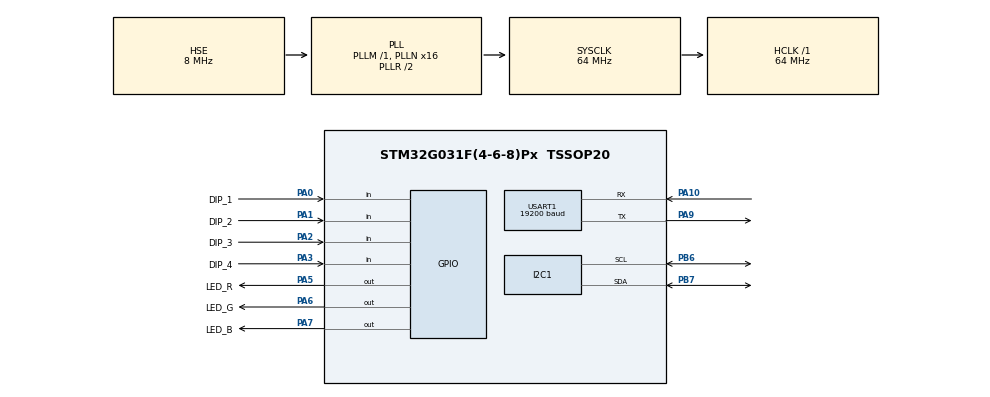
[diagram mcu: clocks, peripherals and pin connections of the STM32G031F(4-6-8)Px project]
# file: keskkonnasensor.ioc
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I2C1.Timing=0x10B17DB5
Mcu.Family=STM32G0
Mcu.Name=STM32G031F(4-6-8)Px
Mcu.Package=TSSOP20
PA0.GPIO_Label=DIP_1
PA0.GPIO_PuPd=GPIO_PULLUP
PA0.Signal=GPIO_Input
PA1.GPIO_Label=DIP_2
PA1.GPIO_PuPd=GPIO_PULLUP
PA1.Signal=GPIO_Input
PA10\ [PA12].Mode=Asynchronous
PA10\ [PA12].Signal=USART1_RX
PA13.Mode=Serial_Wire
PA13.Signal=SYS_SWDIO
PA14-BOOT0.Mode=Serial_Wire
PA14-BOOT0.Signal=SYS_SWCLK
PA14-BOOT0__PA15.StandardMode=true
PA2.GPIO_Label=DIP_3
PA2.GPIO_PuPd=GPIO_PULLUP
PA2.Signal=GPIO_Input
PA3.GPIO_Label=DIP_4
PA3.GPIO_PuPd=GPIO_PULLUP
PA3.Signal=GPIO_Input
PA5.GPIO_Label=LED_R
PA5.Signal=GPIO_Output
PA6.GPIO_Label=LED_G
PA6.Signal=GPIO_Output
PA7.GPIO_Label=LED_B
PA7.Signal=GPIO_Output
PA9\ [PA11].Mode=Asynchronous
PA9\ [PA11].Signal=USART1_TX
PB0__PB1__PB2__PA8.StandardMode=true
PB3__PB4__PB5__PB6.StandardMode=true
PB6.Mode=I2C
PB6.Signal=I2C1_SCL
PB7.Mode=I2C
PB7.Signal=I2C1_SDA
PB7__PB8.StandardMode=true
PC14-OSC32_IN\ (PC14).Mode=HSE-External-Clock-Source
PC14-OSC32_IN\ (PC14).Signal=RCC_OSC_IN
PC14-OSC32_IN\ (PC14)__PB9.StandardMode=true
ProjectManager.HeapSize=0x200
ProjectManager.StackSize=0x400
ProjectManager.TargetToolchain=CMake
RCC.ADCFreq_Value=64000000
RCC.AHBFreq_Value=64000000
RCC.CortexFreq_Value=64000000
RCC.EXTERNAL_CLOCK_VALUE=12288000
RCC.HCLKFreq_Value=64000000
RCC.HSE_VALUE=8000000
RCC.HSI_VALUE=16000000
RCC.LSE_VALUE=32768
RCC.PLLN=16
RCC.PLLSourceVirtual=RCC_PLLSOURCE_HSE
RCC.SYSCLKFreq_VALUE=64000000
RCC.SYSCLKSource=RCC_SYSCLKSOURCE_PLLCLK
RCC.VCOOutputFreq_Value=128000000
USART1.BaudRate=19200
USART1.Parity=PARITY_EVEN
USART1.VirtualMode-Asynchronous=VM_ASYNC
USART1.WordLength=WORDLENGTH_9B
VP_SYS_VS_PINREMAP.Mode=PINREMAP
VP_SYS_VS_PINREMAP_10_12.Mode=PINREMAP_10_12
board=custom

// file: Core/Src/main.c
/* USER CODE BEGIN Header */
/**
  ******************************************************************************
  * @file           : main.c
  * @brief          : Main program body
  ******************************************************************************
  * @attention
  *
  * Copyright (c) 2026 STMicroelectronics.
  * All rights reserved.
  *
  * This software is licensed under terms that can be found in the LICENSE file
  * in the root directory of this software component.
  * If no LICENSE file comes with this software, it is provided AS-IS.
  *
  ******************************************************************************
  */
/* USER CODE END Header */
#include "main.h"
#include "i2c.h"
#include "usart.h"
#include "gpio.h"

/* USER CODE BEGIN Includes */
#include "app.h"
/* USER CODE END Includes */

void SystemClock_Config(void);

int main(void)
{

  /* MCU Configuration--------------------------------------------------------*/

  /* Reset of all peripherals, Initializes the Flash interface and the Systick. */
  HAL_Init();

  /* Configure the system clock */
  SystemClock_Config();

  /* Initialize all configured peripherals */
  MX_GPIO_Init();
  MX_I2C1_Init();
  MX_USART1_UART_Init();
  /* USER CODE BEGIN 2 */
  app_init();   /* our code starts here: see App/app.c */
  /* USER CODE END 2 */

  /* Infinite loop */
  while (1)
  {

    /* USER CODE BEGIN 3 */
    app_poll();
  }
  /* USER CODE END 3 */
}

void SystemClock_Config(void)
{
  RCC_OscInitTypeDef RCC_OscInitStruct = {0};
  RCC_ClkInitTypeDef RCC_ClkInitStruct = {0};

  /** Configure the main internal regulator output voltage
  */
  HAL_PWREx_ControlVoltageScaling(PWR_REGULATOR_VOLTAGE_SCALE1);

  /** Initializes the RCC Oscillators according to the specified parameters
  * in the RCC_OscInitTypeDef structure.
  */
  RCC_OscInitStruct.OscillatorType = RCC_OSCILLATORTYPE_HSE;
  RCC_OscInitStruct.HSEState = RCC_HSE_BYPASS;
  RCC_OscInitStruct.PLL.PLLState = RCC_PLL_ON;
  RCC_OscInitStruct.PLL.PLLSource = RCC_PLLSOURCE_HSE;
  RCC_OscInitStruct.PLL.PLLM = RCC_PLLM_DIV1;
  RCC_OscInitStruct.PLL.PLLN = 16;
  RCC_OscInitStruct.PLL.PLLP = RCC_PLLP_DIV2;
  RCC_OscInitStruct.PLL.PLLQ = RCC_PLLQ_DIV2;
  RCC_OscInitStruct.PLL.PLLR = RCC_PLLR_DIV2;
  if (HAL_RCC_OscConfig(&RCC_OscInitStruct) != HAL_OK)
  {
    Error_Handler();
  }

  /** Initializes the CPU, AHB and APB buses clocks
  */
  RCC_ClkInitStruct.ClockType = RCC_CLOCKTYPE_HCLK|RCC_CLOCKTYPE_SYSCLK
                              |RCC_CLOCKTYPE_PCLK1;
  RCC_ClkInitStruct.SYSCLKSource = RCC_SYSCLKSOURCE_PLLCLK;
  RCC_ClkInitStruct.AHBCLKDivider = RCC_SYSCLK_DIV1;
  RCC_ClkInitStruct.APB1CLKDivider = RCC_HCLK_DIV1;

  if (HAL_RCC_ClockConfig(&RCC_ClkInitStruct, FLASH_LATENCY_2) != HAL_OK)
  {
    Error_Handler();
  }
}

void Error_Handler(void)
{
  __disable_irq();
  while (1)
  {
  }
}
